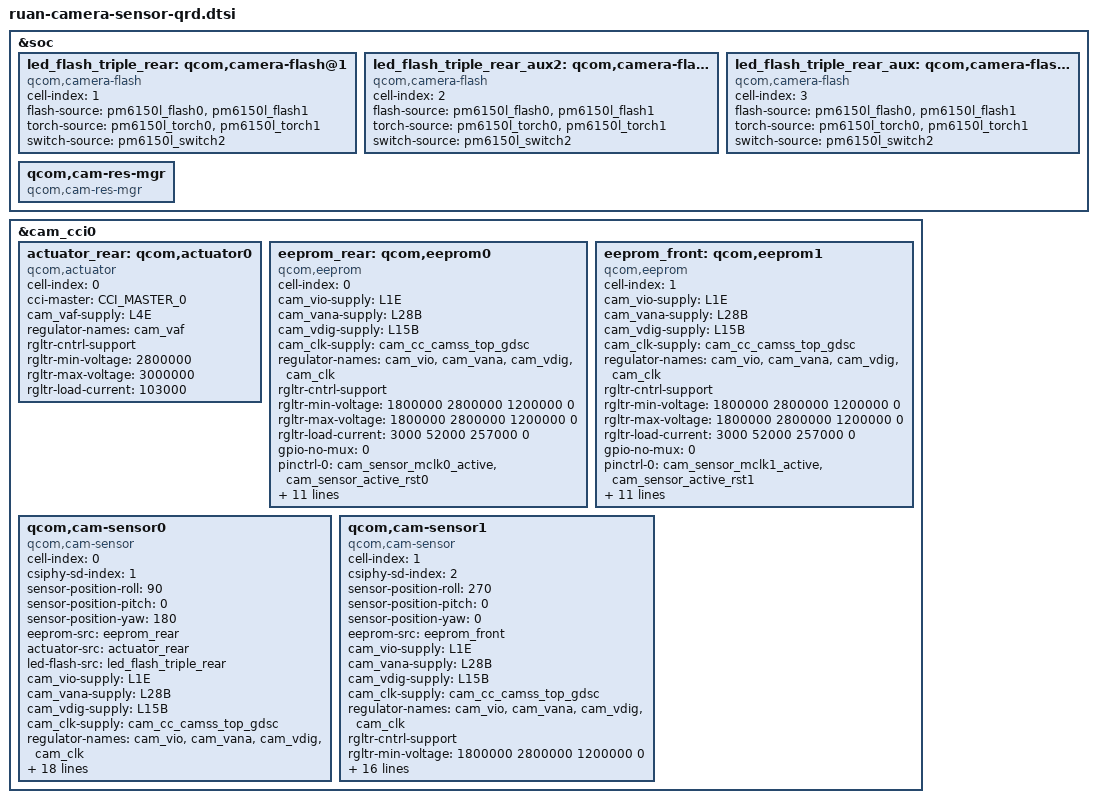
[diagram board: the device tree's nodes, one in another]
#include <dt-bindings/clock/qcom,camcc-parrot.h>
#include <dt-bindings/msm-camera.h>

&soc {
	led_flash_triple_rear: qcom,camera-flash@1 {
		cell-index = <1>;
		compatible = "qcom,camera-flash";
		flash-source = <&pm6150l_flash0 &pm6150l_flash1>;
		torch-source = <&pm6150l_torch0 &pm6150l_torch1>;
		switch-source = <&pm6150l_switch2>;
		status = "ok";
	};

	led_flash_triple_rear_aux2: qcom,camera-flash@2 {
		cell-index = <2>;
		compatible = "qcom,camera-flash";
		flash-source = <&pm6150l_flash0 &pm6150l_flash1>;
		torch-source = <&pm6150l_torch0 &pm6150l_torch1>;
		switch-source = <&pm6150l_switch2>;
		status = "ok";
	};

	led_flash_triple_rear_aux: qcom,camera-flash@3 {
		cell-index = <3>;
		compatible = "qcom,camera-flash";
		flash-source = <&pm6150l_flash0 &pm6150l_flash1>;
		torch-source = <&pm6150l_torch0 &pm6150l_torch1>;
		switch-source = <&pm6150l_switch2>;
		status = "ok";
	};

	qcom,cam-res-mgr {
		compatible = "qcom,cam-res-mgr";
		status = "ok";
	};
};

&cam_cci0 {
	actuator_rear: qcom,actuator0 {
		cell-index = <0>;
		compatible = "qcom,actuator";
		cci-master = <CCI_MASTER_0>;
		cam_vaf-supply = <&L4E>;
		regulator-names = "cam_vaf";
		rgltr-cntrl-support;
		rgltr-min-voltage = <2800000>;
		rgltr-max-voltage = <3000000>;
		rgltr-load-current = <103000>;
	};

	eeprom_rear: qcom,eeprom0 {
		cell-index = <0>;
		compatible = "qcom,eeprom";
		cam_vio-supply = <&L1E>;
		cam_vana-supply = <&L28B>;
		cam_vdig-supply = <&L15B>;
		//cam_vaf-supply = <&L7I>;
		cam_clk-supply = <&cam_cc_camss_top_gdsc>;
		//cam_bob-supply = <&BOB>;
                regulator-names = "cam_vio", "cam_vana", "cam_vdig",
                        /*"cam_vaf",*/ "cam_clk";

		rgltr-cntrl-support;
                rgltr-min-voltage = <1800000 2800000 1200000 0>;
                rgltr-max-voltage = <1800000 2800000 1200000 0>;
                rgltr-load-current = <3000 52000 257000 0>;
		gpio-no-mux = <0>;
		pinctrl-names = "cam_default", "cam_suspend";
		pinctrl-0 = <&cam_sensor_mclk0_active
				 &cam_sensor_active_rst0>;
		pinctrl-1 = <&cam_sensor_mclk0_suspend
				 &cam_sensor_suspend_rst0>;
		gpios = <&tlmm 39 0>,
			<&tlmm 44 0>;
		gpio-reset = <1>;
		gpio-req-tbl-num = <0 1>;
		gpio-req-tbl-flags = <1 0>;
		gpio-req-tbl-label = "CAMIF_MCLK0",
					"CAM_RESET0";
		cci-master = <CCI_MASTER_0>;
		clocks = <&camcc CAM_CC_MCLK0_CLK>;
		clock-names = "cam_clk";
		clock-cntl-level = "nominal";
		clock-rates = <19200000>;
		status = "ok";
	};

	eeprom_front: qcom,eeprom1 {
		cell-index = <1>;
		compatible = "qcom,eeprom";
		cam_vio-supply = <&L1E>;
		cam_vana-supply = <&L28B>;
		cam_vdig-supply = <&L15B>;
		//cam_vaf-supply = <&L7I>;
		cam_clk-supply = <&cam_cc_camss_top_gdsc>;
		//cam_bob-supply = <&BOB>;
                regulator-names = "cam_vio", "cam_vana", "cam_vdig",
                        /*"cam_vaf",*/ "cam_clk";

		rgltr-cntrl-support;
                rgltr-min-voltage = <1800000 2800000 1200000 0>;
                rgltr-max-voltage = <1800000 2800000 1200000 0>;
                rgltr-load-current = <3000 52000 257000 0>;
		gpio-no-mux = <0>;
		pinctrl-names = "cam_default", "cam_suspend";
		pinctrl-0 = <&cam_sensor_mclk1_active
				 &cam_sensor_active_rst1>;
		pinctrl-1 = <&cam_sensor_mclk1_suspend
				 &cam_sensor_suspend_rst1>;
		gpios = <&tlmm 40 0>,
			<&tlmm 45 0>;
		gpio-reset = <1>;
		gpio-req-tbl-num = <0 1>;
		gpio-req-tbl-flags = <1 0>;
		gpio-req-tbl-label = "CAMIF_MCLK1",
					"CAM_RESET1";
		cci-master = <CCI_MASTER_1>;
		clocks = <&camcc CAM_CC_MCLK1_CLK>;
		clock-names = "cam_clk";
		clock-cntl-level = "nominal";
		clock-rates = <19200000>;
		status = "ok";
	};

	qcom,cam-sensor0 {
		cell-index = <0>;
		compatible = "qcom,cam-sensor";
		csiphy-sd-index = <1>;
		sensor-position-roll = <90>;
		sensor-position-pitch = <0>;
		sensor-position-yaw = <180>;
		eeprom-src = <&eeprom_rear>;
		actuator-src = <&actuator_rear>;
		led-flash-src = <&led_flash_triple_rear>;
		cam_vio-supply = <&L1E>;
		cam_vana-supply = <&L28B>;
		cam_vdig-supply = <&L15B>;
		cam_clk-supply = <&cam_cc_camss_top_gdsc>;
		regulator-names = "cam_vio", "cam_vana", "cam_vdig",
			"cam_clk";
		rgltr-cntrl-support;
		rgltr-min-voltage = <1800000 2800000 1200000 0>;
		rgltr-max-voltage = <1800000 2800000 1200000 0>;
		rgltr-load-current = <3000 52000 257000 0>;
		gpio-no-mux = <0>;
		pinctrl-names = "cam_default", "cam_suspend";
		pinctrl-0 = <&cam_sensor_mclk0_active
				 &cam_sensor_active_rst0>;
		pinctrl-1 = <&cam_sensor_mclk0_suspend
				 &cam_sensor_suspend_rst0>;
		gpios = <&tlmm 39 0>,
			<&tlmm 44 0>;
		gpio-reset = <1>;
		gpio-req-tbl-num = <0 1>;
		gpio-req-tbl-flags = <1 0>;
		gpio-req-tbl-label = "CAMIF_MCLK0",
					"CAM_RESET0";
		cci-master = <CCI_MASTER_0>;
		clocks = <&camcc CAM_CC_MCLK0_CLK>;
		clock-names = "cam_clk";
		clock-cntl-level = "nominal";
		clock-rates = <19200000>;
		status = "ok";
	};

	qcom,cam-sensor1 {
		cell-index = <1>;
		compatible = "qcom,cam-sensor";
		csiphy-sd-index = <2>;
		sensor-position-roll = <270>;
		sensor-position-pitch = <0>;
		sensor-position-yaw = <0>;
		eeprom-src = <&eeprom_front>;
		cam_vio-supply = <&L1E>;
		cam_vana-supply = <&L28B>;
		cam_vdig-supply = <&L15B>;
		cam_clk-supply = <&cam_cc_camss_top_gdsc>;
		regulator-names = "cam_vio", "cam_vana", "cam_vdig",
			"cam_clk";
		rgltr-cntrl-support;
		rgltr-min-voltage = <1800000 2800000 1200000 0>;
		rgltr-max-voltage = <1800000 2800000 1200000 0>;
		rgltr-load-current = <3000 52000 257000 0>;
		gpio-no-mux = <0>;
		pinctrl-names = "cam_default", "cam_suspend";
		pinctrl-0 = <&cam_sensor_mclk1_active
				 &cam_sensor_active_rst1>;
		pinctrl-1 = <&cam_sensor_mclk1_suspend
				 &cam_sensor_suspend_rst1>;
		gpios = <&tlmm 40 0>,
			<&tlmm 45 0>;
		gpio-reset = <1>;
		gpio-req-tbl-num = <0 1>;
		gpio-req-tbl-flags = <1 0>;
		gpio-req-tbl-label = "CAMIF_MCLK1",
					"CAM_RESET1";
		cci-master = <CCI_MASTER_1>;
		clocks = <&camcc CAM_CC_MCLK1_CLK>;
		clock-names = "cam_clk";
		clock-cntl-level = "nominal";
		clock-rates = <19200000>;
		status = "ok";
	};
};
